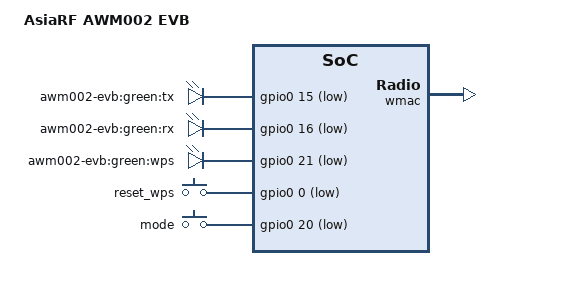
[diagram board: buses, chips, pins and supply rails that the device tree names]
/dts-v1/;

#include "AWM002-4M.dtsi"

/ {
	model = "AsiaRF AWM002 EVB";

	gpio-leds {
		compatible = "gpio-leds";

		tx {
			label = "awm002-evb:green:tx";
			gpios = <&gpio0 15 1>;
		};

		rx {
			label = "awm002-evb:green:rx";
			gpios = <&gpio0 16 1>;
		};

		wps {
			label = "awm002-evb:green:wps";
			gpios = <&gpio0 21 1>;
		};
	};

	gpio-keys-polled {
		compatible = "gpio-keys-polled";
		#address-cells = <1>;
		#size-cells = <0>;
		poll-interval = <20>;

		reset_wps {
			label = "reset_wps";
			gpios = <&gpio0 0 1>;
			linux,code = <0x198>;
		};

		mode {
			label = "mode";
			gpios = <&gpio0 20 1>;
			linux,code = <0x32>;
		};
	};
};

&ethernet {
	mtd-mac-address = <&factory 0x28>;
};

&wmac {
	ralink,mtd-eeprom = <&factory 0>;
};
